# USBSS register map
Vendor: Texas Instruments
Peripheral module from a debugger description file (folder am335x).
Registers are 32-bit, read-write, no defined reset value unless marked. A register's access mark holds for its fields unless they carry their own. Offsets are as the file gives them; lines under a group give offsets from that group; [hi:lo] are bit positions; {n}, {i} and the like mark numbered series; 'fields as' and 'values as' point back to an identical list; <NAME> marks a mode.

## USBSS
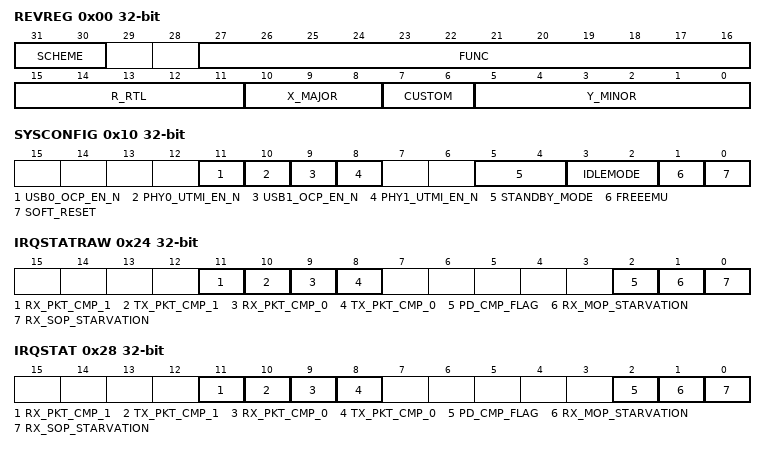
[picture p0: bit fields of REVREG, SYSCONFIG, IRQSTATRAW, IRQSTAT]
0x00 REVREG ro
  [31:30] SCHEME — Used to distinguish between legacy interface scheme and current. 0 = Legacy 1 = Current
  [27:16] FUNC — Function indicates a software compatible module family.
  [15:11] R_RTL — RTL revision. Will vary depending on release.
  [10:8] X_MAJOR — Major revision.
  [7:6] CUSTOM — Custom revision
  [5:0] Y_MINOR — Minor revision. USBSS Revision Register
0x10 SYSCONFIG
  [11] USB0_OCP_EN_N — Active low clock enable for usb0_ocp_clk 0 = enable 1 = disable
  [10] PHY0_UTMI_EN_N — Active low clock enable for phy0_utmi_clk 0 = enable 1 = disable
  [9] USB1_OCP_EN_N — Active low clock enable for usb1_ocp_clk 0 = enable 1 = disable
  [8] PHY1_UTMI_EN_N — Active low clock enable for phy1_utmi_clk 0 = enable 1 = disable
  [5:4] STANDBY_MODE — Configuration of the local initiator state management mode. 0 = force-standby mode. 1 = no-standby mode. 2 = smart-standby mode. 3 = Reserved.
  [3:2] IDLEMODE — Configuration of the local target state management mode. 0 = force-idle mode. 1 = no-idle mode. 2 = smart-idle mode. 3 = Reserved.
  [1] FREEEMU — Sensitivity to emulation (debug) suspend input signal. 0 = sensitive to emulation suspend 1 = NOT sensitive to emulation suspend
  [0] SOFT_RESET — Software reset of USBSS, USB0, and USB1 modules Write 0 = No action. Write 1 = Initiate software reset. Read 0 = Reset done, no action. Read 1 = Reset ongoing.
0x24 IRQSTATRAW
  [11] RX_PKT_CMP_1 — Interrupt status for USB1 Rx CPPI DMA packet completion status
  [10] TX_PKT_CMP_1 — Interrupt status for USB1 Tx CPPI DMA packet completion status
  [9] RX_PKT_CMP_0 — Interrupt status for USB0 Rx CPPI DMA packet completion status
  [8] TX_PKT_CMP_0 — Interrupt status for USB0 Tx CPPI DMA packet completion status
  [2] PD_CMP_FLAG — Interrupt status when the packet is completed, the differ bits is set, and the Packet Descriptor is pushed into the queue manager
  [1] RX_MOP_STARVATION — Interrupt status when queue manager cannot allocate an Rx buffer in the middle of a packet.
  [0] RX_SOP_STARVATION — Interrupt status when queue manager cannot allocate an Rx buffer at the start of a packet. USBSS IRQ_STATUS_RAW Register
0x28 IRQSTAT
  [11] RX_PKT_CMP_1 — Interrupt status for USB1 Rx CPPI DMA packet completion status
  [10] TX_PKT_CMP_1 — Interrupt status for USB1 Tx CPPI DMA packet completion status
  [9] RX_PKT_CMP_0 — Interrupt status for USB0 Rx CPPI DMA packet completion status
  [8] TX_PKT_CMP_0 — Interrupt status for USB0 Tx CPPI DMA packet completion status
  [2] PD_CMP_FLAG — Interrupt status when the packet is completed, the differ bits is set, and the Packet Descriptor is pushed into the queue manager
  [1] RX_MOP_STARVATION — Interrupt status when queue manager cannot allocate an Rx buffer in the middle of a packet.
  [0] RX_SOP_STARVATION — Interrupt status when queue manager cannot allocate an Rx buffer at the start of a packet. USBSS IRQ_STATUS Register
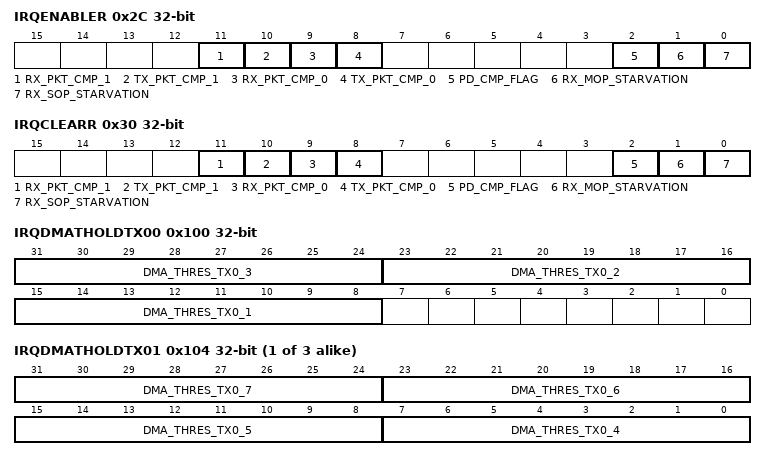
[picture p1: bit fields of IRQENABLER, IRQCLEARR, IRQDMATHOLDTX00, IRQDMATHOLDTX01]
0x2C IRQENABLER
  [11] RX_PKT_CMP_1 — Interrupt enable for USB1 Rx CPPI DMA packet completion status
  [10] TX_PKT_CMP_1 — Interrupt enable for USB1 Tx CPPI DMA packet completion status
  [9] RX_PKT_CMP_0 — Interrupt enable for USB0 Rx CPPI DMA packet completion status
  [8] TX_PKT_CMP_0 — Interrupt enable for USB0 Tx CPPI DMA packet completion status
  [2] PD_CMP_FLAG — Interrupt enable when the packet is completed, the differ bits is set, and the Packet Descriptor is pushed into the queue manager
  [1] RX_MOP_STARVATION — Interrupt enable when queue manager cannot allocate an Rx buffer in the middle of a packet.
  [0] RX_SOP_STARVATION — Interrupt enable when queue manager cannot allocate an Rx buffer at the start of a packet. USBSS IRQ_ENABLE_SET Register
0x30 IRQCLEARR
  [11] RX_PKT_CMP_1 — Interrupt enable for USB1 Rx CPPI DMA packet completion status
  [10] TX_PKT_CMP_1 — Interrupt enable for USB1 Tx CPPI DMA packet completion status
  [9] RX_PKT_CMP_0 — Interrupt enable for USB0 Rx CPPI DMA packet completion status
  [8] TX_PKT_CMP_0 — Interrupt enable for USB0 Tx CPPI DMA packet completion status
  [2] PD_CMP_FLAG — Interrupt enable when the packet is completed, the differ bits is set, and the Packet Descriptor is pushed into the queue manager
  [1] RX_MOP_STARVATION — Interrupt enable when queue manager cannot allocate an Rx buffer in the middle of a packet.
  [0] RX_SOP_STARVATION — Interrupt enable when queue manager cannot allocate an Rx buffer at the start of a packet. USBSS IRQ_ENABLE_CLR Register
0x100 IRQDMATHOLDTX00
  [31:24] DMA_THRES_TX0_3 — DMA threshold value for tx_pkt_cmp_0 for USB0 Endpoint 3.
  [23:16] DMA_THRES_TX0_2 — DMA threshold value for tx_pkt_cmp_0 for USB0 Endpoint 2.
  [15:8] DMA_THRES_TX0_1 — DMA threshold value for tx_pkt_cmp_0 for USB0 Endpoint 1.
{0x100+4i} IRQDMATHOLDTX{i:02} (i=1..3)
  [31:24] DMA_THRES_TX0_{4i+3} — DMA threshold value for tx_pkt_cmp_0 for USB0 Endpoint {4i+3}.
  [23:16] DMA_THRES_TX0_{4i+2} — DMA threshold value for tx_pkt_cmp_0 for USB0 Endpoint {4i+2}.
  [15:8] DMA_THRES_TX0_{4i+1} — DMA threshold value for tx_pkt_cmp_0 for USB0 Endpoint {4i+1}.
  [7:0] DMA_THRES_TX0_{4i} — DMA threshold value for tx_pkt_cmp_0 for USB0 Endpoint {4i}. USBSS IRQ_DMA_THRSHOLD_TX0_{i} Register
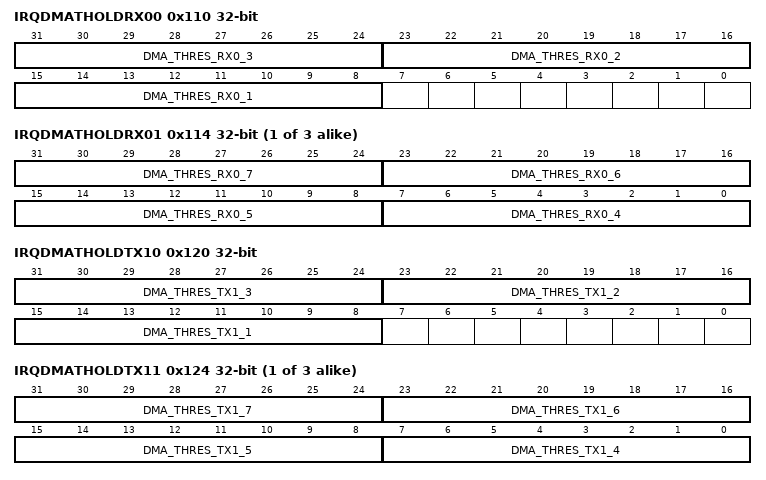
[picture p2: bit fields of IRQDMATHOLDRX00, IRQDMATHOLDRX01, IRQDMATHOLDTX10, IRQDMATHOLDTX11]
0x110 IRQDMATHOLDRX00
  [31:24] DMA_THRES_RX0_3 — DMA threshold value for rx_pkt_cmp_0 for USB0 Endpoint 3.
  [23:16] DMA_THRES_RX0_2 — DMA threshold value for rx_pkt_cmp_0 for USB0 Endpoint 2.
  [15:8] DMA_THRES_RX0_1 — DMA threshold value for rx_pkt_cmp_0 for USB0 Endpoint 1.
{0x110+4i} IRQDMATHOLDRX{i:02} (i=1..3)
  [31:24] DMA_THRES_RX0_{4i+3} — DMA threshold value for rx_pkt_cmp_0 for USB0 Endpoint {4i+3}.
  [23:16] DMA_THRES_RX0_{4i+2} — DMA threshold value for rx_pkt_cmp_0 for USB0 Endpoint {4i+2}.
  [15:8] DMA_THRES_RX0_{4i+1} — DMA threshold value for rx_pkt_cmp_0 for USB0 Endpoint {4i+1}.
  [7:0] DMA_THRES_RX0_{4i} — DMA threshold value for rx_pkt_cmp_0 for USB0 Endpoint {4i}. USBSS IRQ_DMA_THRSHOLD_RX0_{i} Register
0x120 IRQDMATHOLDTX10
  [31:24] DMA_THRES_TX1_3 — DMA threshold value for tx_pkt_cmp_0 for USB1 Endpoint 3.
  [23:16] DMA_THRES_TX1_2 — DMA threshold value for tx_pkt_cmp_0 for USB1 Endpoint 2.
  [15:8] DMA_THRES_TX1_1 — DMA threshold value for tx_pkt_cmp_0 for USB1 Endpoint 1.
{0xF8+4i} IRQDMATHOLDTX{i} (i=11..13)
  [31:24] DMA_THRES_TX1_{4i-37} — DMA threshold value for tx_pkt_cmp_0 for USB1 Endpoint {4i-37}.
  [23:16] DMA_THRES_TX1_{4i-38} — DMA threshold value for tx_pkt_cmp_0 for USB1 Endpoint {4i-38}.
  [15:8] DMA_THRES_TX1_{4i-39} — DMA threshold value for tx_pkt_cmp_0 for USB1 Endpoint {4i-39}.
  [7:0] DMA_THRES_TX1_{4i-40} — DMA threshold value for tx_pkt_cmp_0 for USB1 Endpoint {4i-40}. USBSS IRQ_DMA_THRSHOLD_TX1_{i-10} Register
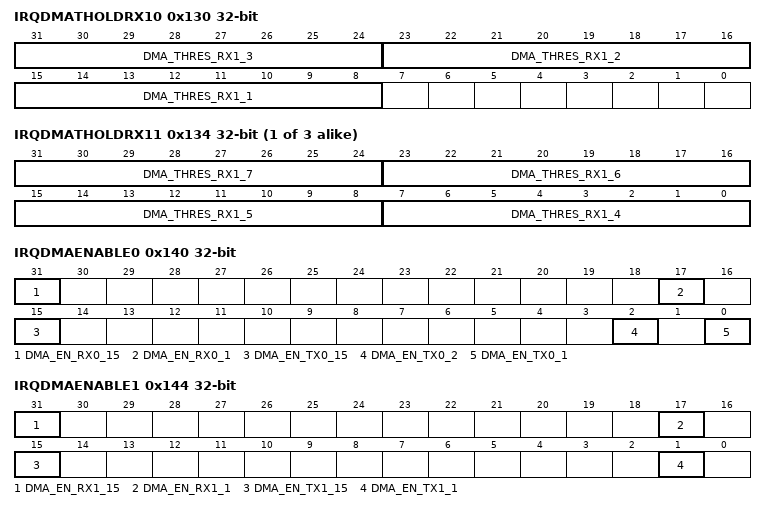
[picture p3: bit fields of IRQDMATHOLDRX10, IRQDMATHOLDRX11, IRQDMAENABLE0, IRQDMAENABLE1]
0x130 IRQDMATHOLDRX10
  [31:24] DMA_THRES_RX1_3 — DMA threshold value for rx_pkt_cmp_0 for USB1 Endpoint 3.
  [23:16] DMA_THRES_RX1_2 — DMA threshold value for rx_pkt_cmp_0 for USB1 Endpoint 2.
  [15:8] DMA_THRES_RX1_1 — DMA threshold value for rx_pkt_cmp_0 for USB1 Endpoint 1.
{0x108+4i} IRQDMATHOLDRX{i} (i=11..13)
  [31:24] DMA_THRES_RX1_{4i-37} — DMA threshold value for rx_pkt_cmp_0 for USB1 Endpoint {4i-37}.
  [23:16] DMA_THRES_RX1_{4i-38} — DMA threshold value for rx_pkt_cmp_0 for USB1 Endpoint {4i-38}.
  [15:8] DMA_THRES_RX1_{4i-39} — DMA threshold value for rx_pkt_cmp_0 for USB1 Endpoint {4i-39}.
  [7:0] DMA_THRES_RX1_{4i-40} — DMA threshold value for rx_pkt_cmp_0 for USB1 Endpoint {4i-40}. USBSS IRQ_DMA_THRSHOLD_RX1_{i-10} Register
0x140 IRQDMAENABLE0
  [31] DMA_EN_RX0_15 — DMA threshold enable value for rx_pkt_cmp_0 for USB0 Endpoint 15. ... ... ... ... ...
  [17] DMA_EN_RX0_1 — DMA threshold enable value for rx_pkt_cmp_0 for USB0 Endpoint 1.
  [15] DMA_EN_TX0_15 — DMA threshold enable value for tx_pkt_cmp_0 for USB0 Endpoint 15. ... ... ... ... ...
  [2] DMA_EN_TX0_2 — DMA threshold enable value for tx_pkt_cmp_0 for USB0 Endpoint 2.
  [0] DMA_EN_TX0_1 — DMA threshold enable value for tx_pkt_cmp_0 for USB0 Endpoint 1.
0x144 IRQDMAENABLE1
  [31] DMA_EN_RX1_15 — DMA threshold enable value for rx_pkt_cmp_1 for USB1 Endpoint 15. ... ... ... ... ...
  [17] DMA_EN_RX1_1 — DMA threshold enable value for rx_pkt_cmp_1 for USB1 Endpoint 1.
  [15] DMA_EN_TX1_15 — DMA threshold enable value for tx_pkt_cmp_1 for USB1 Endpoint 15. ... ... ... ... ...
  [1] DMA_EN_TX1_1 — DMA threshold enable value for tx_pkt_cmp_1 for USB1 Endpoint 1.
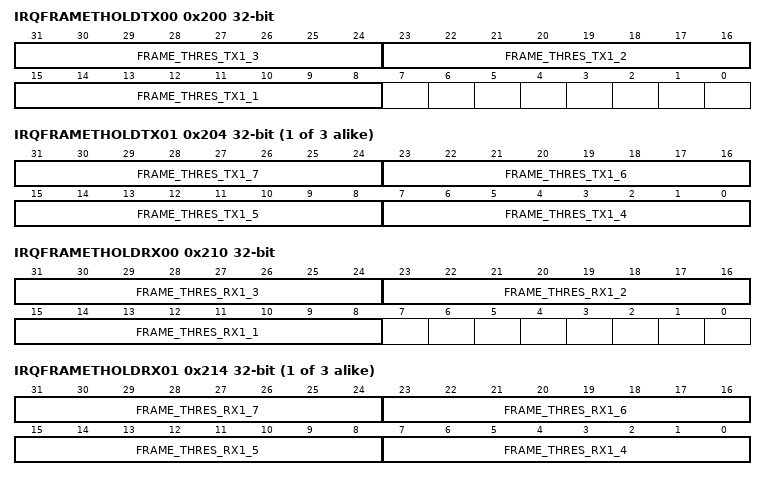
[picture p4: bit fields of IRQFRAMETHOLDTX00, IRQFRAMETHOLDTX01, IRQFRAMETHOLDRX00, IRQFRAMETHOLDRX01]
0x200 IRQFRAMETHOLDTX00
  [31:24] FRAME_THRES_TX1_3 — FRAME threshold value for tx_pkt_cmp_0 for USB0 Endpoint 3.
  [23:16] FRAME_THRES_TX1_2 — FRAME threshold value for tx_pkt_cmp_0 for USB0 Endpoint 2.
  [15:8] FRAME_THRES_TX1_1 — FRAME threshold value for tx_pkt_cmp_0 for USB0 Endpoint 1.
{0x200+4i} IRQFRAMETHOLDTX{i:02} (i=1..3)
  [31:24] FRAME_THRES_TX1_{4i+3} — FRAME threshold value for tx_pkt_cmp_0 for USB0 Endpoint {4i+3}.
  [23:16] FRAME_THRES_TX1_{4i+2} — FRAME threshold value for tx_pkt_cmp_0 for USB0 Endpoint {4i+2}.
  [15:8] FRAME_THRES_TX1_{4i+1} — FRAME threshold value for tx_pkt_cmp_0 for USB0 Endpoint {4i+1}.
  [7:0] FRAME_THRES_TX1_{4i} — FRAME threshold value for tx_pkt_cmp_0 for USB0 Endpoint {4i}. USBSS IRQ_FRAME_THRSHOLD_TX0_{i} Register
0x210 IRQFRAMETHOLDRX00
  [31:24] FRAME_THRES_RX1_3 — FRAME threshold value for rx_pkt_cmp_0 for USB0 Endpoint 3.
  [23:16] FRAME_THRES_RX1_2 — FRAME threshold value for rx_pkt_cmp_0 for USB0 Endpoint 2.
  [15:8] FRAME_THRES_RX1_1 — FRAME threshold value for rx_pkt_cmp_0 for USB0 Endpoint 1.
{0x210+4i} IRQFRAMETHOLDRX{i:02} (i=1..3)
  [31:24] FRAME_THRES_RX1_{4i+3} — FRAME threshold value for rx_pkt_cmp_0 for USB0 Endpoint {4i+3}.
  [23:16] FRAME_THRES_RX1_{4i+2} — FRAME threshold value for rx_pkt_cmp_0 for USB0 Endpoint {4i+2}.
  [15:8] FRAME_THRES_RX1_{4i+1} — FRAME threshold value for rx_pkt_cmp_0 for USB0 Endpoint {4i+1}.
  [7:0] FRAME_THRES_RX1_{4i} — FRAME threshold value for rx_pkt_cmp_0 for USB0 Endpoint {4i}. USBSS IRQ_FRAME_THRSHOLD_RX0_{i} Register
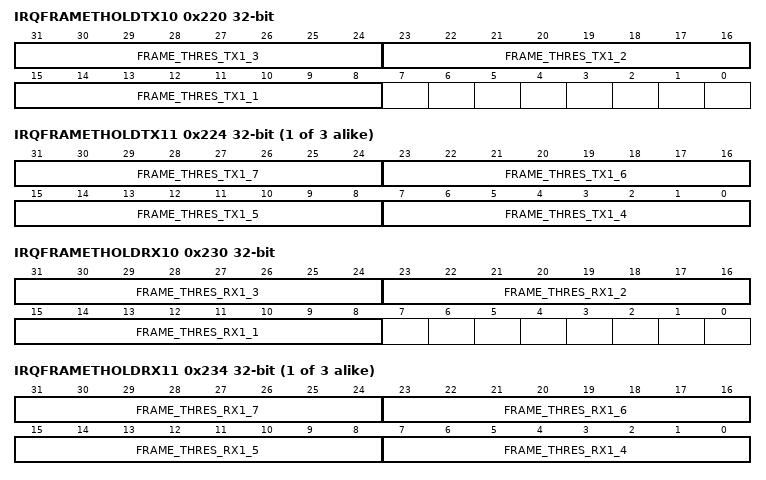
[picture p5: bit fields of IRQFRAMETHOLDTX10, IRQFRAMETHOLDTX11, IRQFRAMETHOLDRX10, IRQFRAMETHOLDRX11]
0x220 IRQFRAMETHOLDTX10
  [31:24] FRAME_THRES_TX1_3 — FRAME threshold value for tx_pkt_cmp_0 for USB1 Endpoint 3.
  [23:16] FRAME_THRES_TX1_2 — FRAME threshold value for tx_pkt_cmp_0 for USB1 Endpoint 2.
  [15:8] FRAME_THRES_TX1_1 — FRAME threshold value for tx_pkt_cmp_0 for USB1 Endpoint 1.
{0x1F8+4i} IRQFRAMETHOLDTX{i} (i=11..13)
  [31:24] FRAME_THRES_TX1_{4i-37} — FRAME threshold value for tx_pkt_cmp_0 for USB1 Endpoint {4i-37}.
  [23:16] FRAME_THRES_TX1_{4i-38} — FRAME threshold value for tx_pkt_cmp_0 for USB1 Endpoint {4i-38}.
  [15:8] FRAME_THRES_TX1_{4i-39} — FRAME threshold value for tx_pkt_cmp_0 for USB1 Endpoint {4i-39}.
  [7:0] FRAME_THRES_TX1_{4i-40} — FRAME threshold value for tx_pkt_cmp_0 for USB1 Endpoint {4i-40}. USBSS IRQ_FRAME_THRSHOLD_TX1_{i-10} Register
0x230 IRQFRAMETHOLDRX10
  [31:24] FRAME_THRES_RX1_3 — FRAME threshold value for rx_pkt_cmp_0 for USB1 Endpoint 3.
  [23:16] FRAME_THRES_RX1_2 — FRAME threshold value for rx_pkt_cmp_0 for USB1 Endpoint 2.
  [15:8] FRAME_THRES_RX1_1 — FRAME threshold value for rx_pkt_cmp_0 for USB1 Endpoint 1.
{0x208+4i} IRQFRAMETHOLDRX{i} (i=11..13)
  [31:24] FRAME_THRES_RX1_{4i-37} — FRAME threshold value for rx_pkt_cmp_0 for USB1 Endpoint {4i-37}.
  [23:16] FRAME_THRES_RX1_{4i-38} — FRAME threshold value for rx_pkt_cmp_0 for USB1 Endpoint {4i-38}.
  [15:8] FRAME_THRES_RX1_{4i-39} — FRAME threshold value for rx_pkt_cmp_0 for USB1 Endpoint {4i-39}.
  [7:0] FRAME_THRES_RX1_{4i-40} — FRAME threshold value for rx_pkt_cmp_0 for USB1 Endpoint {4i-40}. USBSS IRQ_FRAME_THRSHOLD_RX1_{i-10} Register
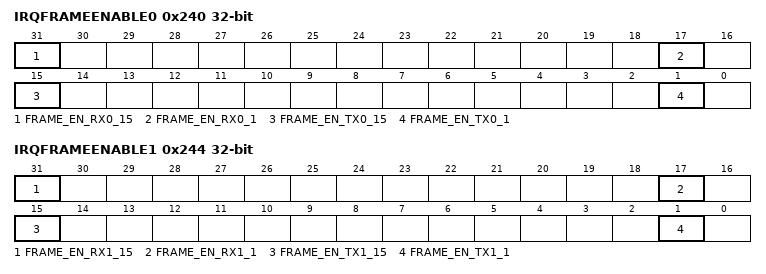
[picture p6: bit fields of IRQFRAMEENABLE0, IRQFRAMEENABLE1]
0x240 IRQFRAMEENABLE0
  [31] FRAME_EN_RX0_15 — FRAME threshold enable value for rx_pkt_cmp_0 for USB0 Endpoint 15. ... ... ... ... ...
  [17] FRAME_EN_RX0_1 — FRAME threshold enable value for rx_pkt_cmp_0 for USB0 Endpoint 1.
  [15] FRAME_EN_TX0_15 — FRAME threshold enable value for tx_pkt_cmp_0 for USB0 Endpoint 15. ... ... ... ... ...
  [1] FRAME_EN_TX0_1 — FRAME threshold enable value for tx_pkt_cmp_0 for USB0 Endpoint 1.
0x244 IRQFRAMEENABLE1
  [31] FRAME_EN_RX1_15 — FRAME threshold enable value for rx_pkt_cmp_1 for USB1 Endpoint 15. ... ... ... ... ...
  [17] FRAME_EN_RX1_1 — FRAME threshold enable value for rx_pkt_cmp_1 for USB1 Endpoint 1.
  [15] FRAME_EN_TX1_15 — FRAME threshold enable value for tx_pkt_cmp_1 for USB1 Endpoint 15. ... ... ... ... ...
  [1] FRAME_EN_TX1_1 — FRAME threshold enable value for tx_pkt_cmp_1 for USB1 Endpoint 1.
